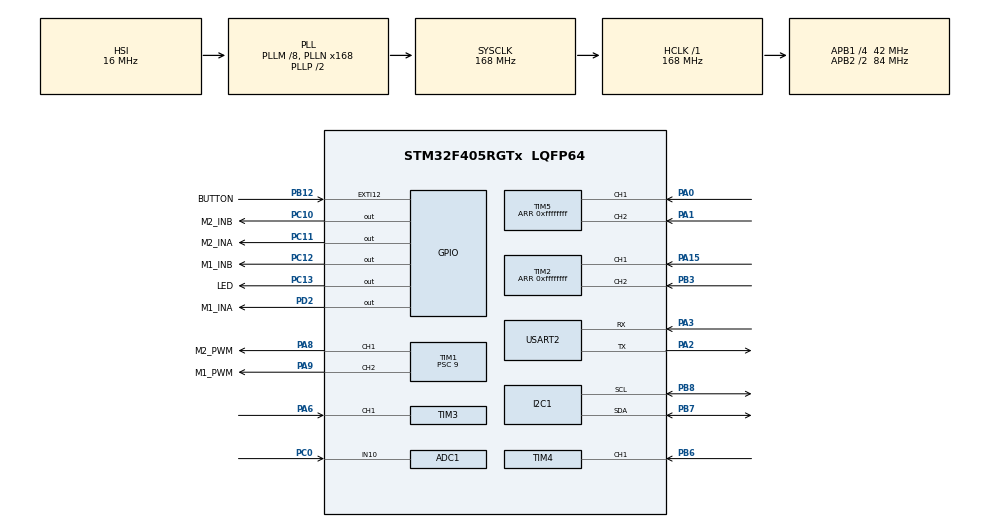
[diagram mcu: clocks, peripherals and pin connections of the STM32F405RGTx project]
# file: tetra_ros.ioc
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ADC1.Channel-4\#ChannelRegularConversion=ADC_CHANNEL_10
ADC1.Channel-5\#ChannelRegularConversion=ADC_CHANNEL_10
ADC1.ContinuousConvMode=ENABLE
ADC1.DMAContinuousRequests=ENABLE
ADC1.EOCSelection=ADC_EOC_SEQ_CONV
ADC1.ExternalTrigConv=ADC_SOFTWARE_START
ADC1.NbrOfConversion=2
ADC1.NbrOfConversionFlag=1
ADC1.Rank-4\#ChannelRegularConversion=1
ADC1.Rank-5\#ChannelRegularConversion=2
ADC1.SamplingTime-4\#ChannelRegularConversion=ADC_SAMPLETIME_480CYCLES
ADC1.SamplingTime-5\#ChannelRegularConversion=ADC_SAMPLETIME_480CYCLES
ADC1.ScanConvMode=ENABLE
ADC1.master=1
Dma.ADC1.2.Direction=DMA_PERIPH_TO_MEMORY
Dma.ADC1.2.FIFOMode=DMA_FIFOMODE_DISABLE
Dma.ADC1.2.Instance=DMA2_Stream0
Dma.ADC1.2.MemDataAlignment=DMA_MDATAALIGN_HALFWORD
Dma.ADC1.2.MemInc=DMA_MINC_ENABLE
Dma.ADC1.2.Mode=DMA_CIRCULAR
Dma.ADC1.2.PeriphDataAlignment=DMA_PDATAALIGN_HALFWORD
Dma.ADC1.2.PeriphInc=DMA_PINC_DISABLE
Dma.ADC1.2.Priority=DMA_PRIORITY_LOW
Dma.Request0=USART2_RX
Dma.Request1=USART2_TX
Dma.Request2=ADC1
Dma.USART2_RX.0.Direction=DMA_PERIPH_TO_MEMORY
Dma.USART2_RX.0.FIFOMode=DMA_FIFOMODE_DISABLE
Dma.USART2_RX.0.Instance=DMA1_Stream5
Dma.USART2_RX.0.MemDataAlignment=DMA_MDATAALIGN_BYTE
Dma.USART2_RX.0.MemInc=DMA_MINC_ENABLE
Dma.USART2_RX.0.Mode=DMA_CIRCULAR
Dma.USART2_RX.0.PeriphDataAlignment=DMA_PDATAALIGN_BYTE
Dma.USART2_RX.0.PeriphInc=DMA_PINC_DISABLE
Dma.USART2_RX.0.Priority=DMA_PRIORITY_LOW
Dma.USART2_TX.1.Direction=DMA_MEMORY_TO_PERIPH
Dma.USART2_TX.1.FIFOMode=DMA_FIFOMODE_DISABLE
Dma.USART2_TX.1.Instance=DMA1_Stream6
Dma.USART2_TX.1.MemDataAlignment=DMA_MDATAALIGN_BYTE
Dma.USART2_TX.1.MemInc=DMA_MINC_ENABLE
Dma.USART2_TX.1.Mode=DMA_NORMAL
Dma.USART2_TX.1.PeriphDataAlignment=DMA_PDATAALIGN_BYTE
Dma.USART2_TX.1.PeriphInc=DMA_PINC_DISABLE
Dma.USART2_TX.1.Priority=DMA_PRIORITY_LOW
I2C1.I2C_Mode=I2C_Fast
Mcu.Family=STM32F4
Mcu.Name=STM32F405RGTx
Mcu.Package=LQFP64
NVIC.DMA1_Stream5_IRQn=true\:0\:0\:false\:false\:true\:false\:true
NVIC.DMA1_Stream6_IRQn=true\:0\:0\:false\:false\:true\:false\:true
NVIC.DMA2_Stream0_IRQn=true\:0\:0\:false\:false\:true\:true\:true
NVIC.EXTI15_10_IRQn=true\:0\:0\:false\:false\:true\:true\:true
NVIC.PriorityGroup=NVIC_PRIORITYGROUP_4
NVIC.TIM3_IRQn=true\:0\:0\:false\:false\:true\:true\:true
NVIC.USART2_IRQn=true\:0\:0\:false\:false\:true\:true\:true
PA0-WKUP.Signal=S_TIM5_CH1
PA1.Signal=S_TIM5_CH2
PA13.Mode=Serial_Wire
PA13.Signal=SYS_JTMS-SWDIO
PA14.Mode=Serial_Wire
PA14.Signal=SYS_JTCK-SWCLK
PA15.Signal=S_TIM2_CH1_ETR
PA2.Mode=Asynchronous
PA2.Signal=USART2_TX
PA3.Mode=Asynchronous
PA3.Signal=USART2_RX
PA6.Signal=S_TIM3_CH1
PA8.GPIO_Label=M2_PWM
PA8.Signal=S_TIM1_CH1
PA9.GPIO_Label=M1_PWM
PA9.Signal=S_TIM1_CH2
PB12.GPIO_Label=BUTTON
PB12.GPIO_ModeDefaultEXTI=GPIO_MODE_IT_FALLING
PB12.Signal=GPXTI12
PB3.Signal=S_TIM2_CH2
PB6.Signal=S_TIM4_CH1
PB7.Mode=I2C
PB7.Signal=I2C1_SDA
PB8.Mode=I2C
PB8.Signal=I2C1_SCL
PC0.Signal=ADCx_IN10
PC10.GPIO_Label=M2_INB
PC10.Signal=GPIO_Output
PC11.GPIO_Label=M2_INA
PC11.Signal=GPIO_Output
PC12.GPIO_Label=M1_INB
PC12.Signal=GPIO_Output
PC13-ANTI_TAMP.GPIO_Label=LED
PC13-ANTI_TAMP.Signal=GPIO_Output
PD2.GPIO_Label=M1_INA
PD2.Signal=GPIO_Output
ProjectManager.HeapSize=0x200
ProjectManager.StackSize=0x400
ProjectManager.TargetToolchain=STM32CubeIDE
RCC.48MHZClocksFreq_Value=84000000
RCC.AHBFreq_Value=168000000
RCC.APB1CLKDivider=RCC_HCLK_DIV4
RCC.APB1Freq_Value=42000000
RCC.APB1TimFreq_Value=84000000
RCC.APB2CLKDivider=RCC_HCLK_DIV2
RCC.APB2Freq_Value=84000000
RCC.APB2TimFreq_Value=168000000
RCC.CortexFreq_Value=168000000
RCC.HCLKFreq_Value=168000000
RCC.HSE_VALUE=25000000
RCC.HSI_VALUE=16000000
RCC.LSE_VALUE=32768
RCC.PLLM=8
RCC.PLLN=168
RCC.SYSCLKFreq_VALUE=168000000
RCC.SYSCLKSource=RCC_SYSCLKSOURCE_PLLCLK
RCC.VCOOutputFreq_Value=336000000
SH.ADCx_IN10.0=ADC1_IN10,IN10
SH.S_TIM1_CH1.0=TIM1_CH1,PWM Generation1 CH1
SH.S_TIM1_CH2.0=TIM1_CH2,PWM Generation2 CH2
SH.S_TIM2_CH1_ETR.0=TIM2_CH1,Encoder_Interface
SH.S_TIM2_CH2.0=TIM2_CH2,Encoder_Interface
SH.S_TIM3_CH1.0=TIM3_CH1,PWM_Input_1
SH.S_TIM4_CH1.0=TIM4_CH1,PWM_Input_1
SH.S_TIM5_CH1.0=TIM5_CH1,Encoder_Interface
SH.S_TIM5_CH2.0=TIM5_CH2,Encoder_Interface
TIM1.Channel-PWM\ Generation1\ CH1=TIM_CHANNEL_1
TIM1.Channel-PWM\ Generation2\ CH2=TIM_CHANNEL_2
TIM1.Period=999
TIM1.Prescaler=9
TIM14.Period=0xFFFF
TIM14.Prescaler=83
TIM2.EncoderMode=TIM_ENCODERMODE_TI12
TIM2.Period=0xffffffff
TIM3.Period=19999
TIM3.Prescaler=83
TIM4.Period=19999
TIM4.Prescaler=83
TIM5.EncoderMode=TIM_ENCODERMODE_TI12
TIM5.Period=0xffffffff
USART2.VirtualMode=VM_ASYNC
VP_IWDG_VS_IWDG.Mode=IWDG_Activate
VP_TIM14_VS_ClockSourceINT.Mode=Enable_Timer
VP_TIM1_VS_ClockSourceINT.Mode=Internal
VP_TIM3_VS_ClockSourceINT.Mode=Internal
VP_TIM4_VS_ClockSourceINT.Mode=Internal
board=SouthBridge

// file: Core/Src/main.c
/* USER CODE BEGIN Header */
/**
  ******************************************************************************
  * @file           : main.c
  * @brief          : Main program body
  ******************************************************************************
  * @attention
  *
  * <h2><center>&copy; Copyright (c) 2020 STMicroelectronics.
  * All rights reserved.</center></h2>
  *
  * This software component is licensed by ST under BSD 3-Clause license,
  * the "License"; You may not use this file except in compliance with the
  * License. You may obtain a copy of the License at:
  *                        opensource.org/licenses/BSD-3-Clause
  *
  ******************************************************************************
  */
/* USER CODE END Header */

#include "main.h"
#include "tetraROS.h"

ADC_HandleTypeDef hadc1;
DMA_HandleTypeDef hdma_adc1;

I2C_HandleTypeDef hi2c1;

TIM_HandleTypeDef htim1;
TIM_HandleTypeDef htim3;
TIM_HandleTypeDef htim4;

UART_HandleTypeDef huart2;
DMA_HandleTypeDef hdma_usart2_rx;
DMA_HandleTypeDef hdma_usart2_tx;

void SystemClock_Config(void);
static void MX_GPIO_Init(void);
static void MX_DMA_Init(void);
static void MX_TIM1_Init(void);
static void MX_TIM2_Init(void);
static void MX_TIM5_Init(void);
static void MX_ADC1_Init(void);
static void MX_TIM3_Init(void);
static void MX_TIM4_Init(void);
static void MX_USART2_UART_Init(void);
static void MX_I2C1_Init(void);
static void MX_TIM14_Init(void);
static void MX_IWDG_Init(void);

int main(void)
{

  /* MCU Configuration--------------------------------------------------------*/

  /* Reset of all peripherals, Initializes the Flash interface and the Systick. */
  HAL_Init();

  /* Configure the system clock */
  SystemClock_Config();

  /* Initialize all configured peripherals */
  MX_GPIO_Init();
  MX_DMA_Init();
  MX_TIM1_Init();
  MX_TIM2_Init();
  MX_TIM5_Init();
  MX_ADC1_Init();
  MX_TIM3_Init();
  MX_TIM4_Init();
  MX_USART2_UART_Init();
  MX_I2C1_Init();
  MX_TIM14_Init();
  MX_IWDG_Init();
  /* USER CODE BEGIN 2 */
  initTetraROS();
  /* USER CODE END 2 */

  /* Infinite loop */
  while (1)
  {

    /* USER CODE BEGIN 3 */
	  loopTetraROS();
  }
  /* USER CODE END 3 */
}

void SystemClock_Config(void)
{
  RCC_OscInitTypeDef RCC_OscInitStruct = {0};
  RCC_ClkInitTypeDef RCC_ClkInitStruct = {0};

  /** Configure the main internal regulator output voltage
  */
  __HAL_RCC_PWR_CLK_ENABLE();
  __HAL_PWR_VOLTAGESCALING_CONFIG(PWR_REGULATOR_VOLTAGE_SCALE1);
  /** Initializes the CPU, AHB and APB busses clocks
  */
  RCC_OscInitStruct.OscillatorType = RCC_OSCILLATORTYPE_HSI|RCC_OSCILLATORTYPE_LSI;
  RCC_OscInitStruct.HSIState = RCC_HSI_ON;
  RCC_OscInitStruct.HSICalibrationValue = RCC_HSICALIBRATION_DEFAULT;
  RCC_OscInitStruct.LSIState = RCC_LSI_ON;
  RCC_OscInitStruct.PLL.PLLState = RCC_PLL_ON;
  RCC_OscInitStruct.PLL.PLLSource = RCC_PLLSOURCE_HSI;
  RCC_OscInitStruct.PLL.PLLM = 8;
  RCC_OscInitStruct.PLL.PLLN = 168;
  RCC_OscInitStruct.PLL.PLLP = RCC_PLLP_DIV2;
  RCC_OscInitStruct.PLL.PLLQ = 4;
  if (HAL_RCC_OscConfig(&RCC_OscInitStruct) != HAL_OK)
  {
    Error_Handler();
  }
  /** Initializes the CPU, AHB and APB busses clocks
  */
  RCC_ClkInitStruct.ClockType = RCC_CLOCKTYPE_HCLK|RCC_CLOCKTYPE_SYSCLK
                              |RCC_CLOCKTYPE_PCLK1|RCC_CLOCKTYPE_PCLK2;
  RCC_ClkInitStruct.SYSCLKSource = RCC_SYSCLKSOURCE_PLLCLK;
  RCC_ClkInitStruct.AHBCLKDivider = RCC_SYSCLK_DIV1;
  RCC_ClkInitStruct.APB1CLKDivider = RCC_HCLK_DIV4;
  RCC_ClkInitStruct.APB2CLKDivider = RCC_HCLK_DIV2;

  if (HAL_RCC_ClockConfig(&RCC_ClkInitStruct, FLASH_LATENCY_5) != HAL_OK)
  {
    Error_Handler();
  }
}

static void MX_ADC1_Init(void)
{

  ADC_ChannelConfTypeDef sConfig = {0};

  /** Configure the global features of the ADC (Clock, Resolution, Data Alignment and number of conversion)
  */
  hadc1.Instance = ADC1;
  hadc1.Init.ClockPrescaler = ADC_CLOCK_SYNC_PCLK_DIV4;
  hadc1.Init.Resolution = ADC_RESOLUTION_12B;
  hadc1.Init.ScanConvMode = ENABLE;
  hadc1.Init.ContinuousConvMode = ENABLE;
  hadc1.Init.DiscontinuousConvMode = DISABLE;
  hadc1.Init.ExternalTrigConvEdge = ADC_EXTERNALTRIGCONVEDGE_NONE;
  hadc1.Init.ExternalTrigConv = ADC_SOFTWARE_START;
  hadc1.Init.DataAlign = ADC_DATAALIGN_RIGHT;
  hadc1.Init.NbrOfConversion = 2;
  hadc1.Init.DMAContinuousRequests = ENABLE;
  hadc1.Init.EOCSelection = ADC_EOC_SEQ_CONV;
  if (HAL_ADC_Init(&hadc1) != HAL_OK)
  {
    Error_Handler();
  }
  /** Configure for the selected ADC regular channel its corresponding rank in the sequencer and its sample time.
  */
  sConfig.Channel = ADC_CHANNEL_10;
  sConfig.Rank = 1;
  sConfig.SamplingTime = ADC_SAMPLETIME_480CYCLES;
  if (HAL_ADC_ConfigChannel(&hadc1, &sConfig) != HAL_OK)
  {
    Error_Handler();
  }
  /** Configure for the selected ADC regular channel its corresponding rank in the sequencer and its sample time.
  */
  sConfig.Rank = 2;
  if (HAL_ADC_ConfigChannel(&hadc1, &sConfig) != HAL_OK)
  {
    Error_Handler();
  }

}

static void MX_I2C1_Init(void)
{

  hi2c1.Instance = I2C1;
  hi2c1.Init.ClockSpeed = 400000;
  hi2c1.Init.DutyCycle = I2C_DUTYCYCLE_2;
  hi2c1.Init.OwnAddress1 = 0;
  hi2c1.Init.AddressingMode = I2C_ADDRESSINGMODE_7BIT;
  hi2c1.Init.DualAddressMode = I2C_DUALADDRESS_DISABLE;
  hi2c1.Init.OwnAddress2 = 0;
  hi2c1.Init.GeneralCallMode = I2C_GENERALCALL_DISABLE;
  hi2c1.Init.NoStretchMode = I2C_NOSTRETCH_DISABLE;
  if (HAL_I2C_Init(&hi2c1) != HAL_OK)
  {
    Error_Handler();
  }

}

static void MX_IWDG_Init(void)
{

  hiwdg.Instance = IWDG;
  hiwdg.Init.Prescaler = IWDG_PRESCALER_16;
  hiwdg.Init.Reload = 4095;
  if (HAL_IWDG_Init(&hiwdg) != HAL_OK)
  {
    Error_Handler();
  }

}

static void MX_TIM1_Init(void)
{

  TIM_ClockConfigTypeDef sClockSourceConfig = {0};
  TIM_MasterConfigTypeDef sMasterConfig = {0};
  TIM_OC_InitTypeDef sConfigOC = {0};
  TIM_BreakDeadTimeConfigTypeDef sBreakDeadTimeConfig = {0};

  htim1.Instance = TIM1;
  htim1.Init.Prescaler = 9;
  htim1.Init.CounterMode = TIM_COUNTERMODE_UP;
  htim1.Init.Period = 999;
  htim1.Init.ClockDivision = TIM_CLOCKDIVISION_DIV1;
  htim1.Init.RepetitionCounter = 0;
  htim1.Init.AutoReloadPreload = TIM_AUTORELOAD_PRELOAD_DISABLE;
  if (HAL_TIM_Base_Init(&htim1) != HAL_OK)
  {
    Error_Handler();
  }
  sClockSourceConfig.ClockSource = TIM_CLOCKSOURCE_INTERNAL;
  if (HAL_TIM_ConfigClockSource(&htim1, &sClockSourceConfig) != HAL_OK)
  {
    Error_Handler();
  }
  if (HAL_TIM_PWM_Init(&htim1) != HAL_OK)
  {
    Error_Handler();
  }
  sMasterConfig.MasterOutputTrigger = TIM_TRGO_RESET;
  sMasterConfig.MasterSlaveMode = TIM_MASTERSLAVEMODE_DISABLE;
  if (HAL_TIMEx_MasterConfigSynchronization(&htim1, &sMasterConfig) != HAL_OK)
  {
    Error_Handler();
  }
  sConfigOC.OCMode = TIM_OCMODE_PWM1;
  sConfigOC.Pulse = 0;
  sConfigOC.OCPolarity = TIM_OCPOLARITY_HIGH;
  sConfigOC.OCNPolarity = TIM_OCNPOLARITY_HIGH;
  sConfigOC.OCFastMode = TIM_OCFAST_DISABLE;
  sConfigOC.OCIdleState = TIM_OCIDLESTATE_RESET;
  sConfigOC.OCNIdleState = TIM_OCNIDLESTATE_RESET;
  if (HAL_TIM_PWM_ConfigChannel(&htim1, &sConfigOC, TIM_CHANNEL_1) != HAL_OK)
  {
    Error_Handler();
  }
  if (HAL_TIM_PWM_ConfigChannel(&htim1, &sConfigOC, TIM_CHANNEL_2) != HAL_OK)
  {
    Error_Handler();
  }
  sBreakDeadTimeConfig.OffStateRunMode = TIM_OSSR_DISABLE;
  sBreakDeadTimeConfig.OffStateIDLEMode = TIM_OSSI_DISABLE;
  sBreakDeadTimeConfig.LockLevel = TIM_LOCKLEVEL_OFF;
  sBreakDeadTimeConfig.DeadTime = 0;
  sBreakDeadTimeConfig.BreakState = TIM_BREAK_DISABLE;
  sBreakDeadTimeConfig.BreakPolarity = TIM_BREAKPOLARITY_HIGH;
  sBreakDeadTimeConfig.AutomaticOutput = TIM_AUTOMATICOUTPUT_DISABLE;
  if (HAL_TIMEx_ConfigBreakDeadTime(&htim1, &sBreakDeadTimeConfig) != HAL_OK)
  {
    Error_Handler();
  }
  HAL_TIM_MspPostInit(&htim1);

}

static void MX_TIM2_Init(void)
{

  TIM_Encoder_InitTypeDef sConfig = {0};
  TIM_MasterConfigTypeDef sMasterConfig = {0};

  htim2.Instance = TIM2;
  htim2.Init.Prescaler = 0;
  htim2.Init.CounterMode = TIM_COUNTERMODE_UP;
  htim2.Init.Period = 0xffffffff;
  htim2.Init.ClockDivision = TIM_CLOCKDIVISION_DIV1;
  htim2.Init.AutoReloadPreload = TIM_AUTORELOAD_PRELOAD_DISABLE;
  sConfig.EncoderMode = TIM_ENCODERMODE_TI12;
  sConfig.IC1Polarity = TIM_ICPOLARITY_RISING;
  sConfig.IC1Selection = TIM_ICSELECTION_DIRECTTI;
  sConfig.IC1Prescaler = TIM_ICPSC_DIV1;
  sConfig.IC1Filter = 0;
  sConfig.IC2Polarity = TIM_ICPOLARITY_RISING;
  sConfig.IC2Selection = TIM_ICSELECTION_DIRECTTI;
  sConfig.IC2Prescaler = TIM_ICPSC_DIV1;
  sConfig.IC2Filter = 0;
  if (HAL_TIM_Encoder_Init(&htim2, &sConfig) != HAL_OK)
  {
    Error_Handler();
  }
  sMasterConfig.MasterOutputTrigger = TIM_TRGO_RESET;
  sMasterConfig.MasterSlaveMode = TIM_MASTERSLAVEMODE_DISABLE;
  if (HAL_TIMEx_MasterConfigSynchronization(&htim2, &sMasterConfig) != HAL_OK)
  {
    Error_Handler();
  }

}

static void MX_TIM3_Init(void)
{

  TIM_ClockConfigTypeDef sClockSourceConfig = {0};
  TIM_SlaveConfigTypeDef sSlaveConfig = {0};
  TIM_IC_InitTypeDef sConfigIC = {0};
  TIM_MasterConfigTypeDef sMasterConfig = {0};

  htim3.Instance = TIM3;
  htim3.Init.Prescaler = 83;
  htim3.Init.CounterMode = TIM_COUNTERMODE_UP;
  htim3.Init.Period = 19999;
  htim3.Init.ClockDivision = TIM_CLOCKDIVISION_DIV1;
  htim3.Init.AutoReloadPreload = TIM_AUTORELOAD_PRELOAD_DISABLE;
  if (HAL_TIM_Base_Init(&htim3) != HAL_OK)
  {
    Error_Handler();
  }
  sClockSourceConfig.ClockSource = TIM_CLOCKSOURCE_INTERNAL;
  if (HAL_TIM_ConfigClockSource(&htim3, &sClockSourceConfig) != HAL_OK)
  {
    Error_Handler();
  }
  if (HAL_TIM_IC_Init(&htim3) != HAL_OK)
  {
    Error_Handler();
  }
  sSlaveConfig.SlaveMode = TIM_SLAVEMODE_RESET;
  sSlaveConfig.InputTrigger = TIM_TS_TI1FP1;
  sSlaveConfig.TriggerPolarity = TIM_INPUTCHANNELPOLARITY_RISING;
  sSlaveConfig.TriggerPrescaler = TIM_ICPSC_DIV1;
  sSlaveConfig.TriggerFilter = 0;
  if (HAL_TIM_SlaveConfigSynchro(&htim3, &sSlaveConfig) != HAL_OK)
  {
    Error_Handler();
  }
  sConfigIC.ICPolarity = TIM_INPUTCHANNELPOLARITY_RISING;
  sConfigIC.ICSelection = TIM_ICSELECTION_DIRECTTI;
  sConfigIC.ICPrescaler = TIM_ICPSC_DIV1;
  sConfigIC.ICFilter = 0;
  if (HAL_TIM_IC_ConfigChannel(&htim3, &sConfigIC, TIM_CHANNEL_1) != HAL_OK)
  {
    Error_Handler();
  }
  sConfigIC.ICPolarity = TIM_INPUTCHANNELPOLARITY_FALLING;
  sConfigIC.ICSelection = TIM_ICSELECTION_INDIRECTTI;
  if (HAL_TIM_IC_ConfigChannel(&htim3, &sConfigIC, TIM_CHANNEL_2) != HAL_OK)
  {
    Error_Handler();
  }
  sMasterConfig.MasterOutputTrigger = TIM_TRGO_RESET;
  sMasterConfig.MasterSlaveMode = TIM_MASTERSLAVEMODE_DISABLE;
  if (HAL_TIMEx_MasterConfigSynchronization(&htim3, &sMasterConfig) != HAL_OK)
  {
    Error_Handler();
  }

}

static void MX_TIM4_Init(void)
{

  TIM_ClockConfigTypeDef sClockSourceConfig = {0};
  TIM_SlaveConfigTypeDef sSlaveConfig = {0};
  TIM_IC_InitTypeDef sConfigIC = {0};
  TIM_MasterConfigTypeDef sMasterConfig = {0};

  htim4.Instance = TIM4;
  htim4.Init.Prescaler = 83;
  htim4.Init.CounterMode = TIM_COUNTERMODE_UP;
  htim4.Init.Period = 19999;
  htim4.Init.ClockDivision = TIM_CLOCKDIVISION_DIV1;
  htim4.Init.AutoReloadPreload = TIM_AUTORELOAD_PRELOAD_DISABLE;
  if (HAL_TIM_Base_Init(&htim4) != HAL_OK)
  {
    Error_Handler();
  }
  sClockSourceConfig.ClockSource = TIM_CLOCKSOURCE_INTERNAL;
  if (HAL_TIM_ConfigClockSource(&htim4, &sClockSourceConfig) != HAL_OK)
  {
    Error_Handler();
  }
  if (HAL_TIM_IC_Init(&htim4) != HAL_OK)
  {
    Error_Handler();
  }
  sSlaveConfig.SlaveMode = TIM_SLAVEMODE_RESET;
  sSlaveConfig.InputTrigger = TIM_TS_TI1FP1;
  sSlaveConfig.TriggerPolarity = TIM_INPUTCHANNELPOLARITY_RISING;
  sSlaveConfig.TriggerPrescaler = TIM_ICPSC_DIV1;
  sSlaveConfig.TriggerFilter = 0;
  if (HAL_TIM_SlaveConfigSynchro(&htim4, &sSlaveConfig) != HAL_OK)
  {
    Error_Handler();
  }
  sConfigIC.ICPolarity = TIM_INPUTCHANNELPOLARITY_RISING;
  sConfigIC.ICSelection = TIM_ICSELECTION_DIRECTTI;
  sConfigIC.ICPrescaler = TIM_ICPSC_DIV1;
  sConfigIC.ICFilter = 0;
  if (HAL_TIM_IC_ConfigChannel(&htim4, &sConfigIC, TIM_CHANNEL_1) != HAL_OK)
  {
    Error_Handler();
  }
  sConfigIC.ICPolarity = TIM_INPUTCHANNELPOLARITY_FALLING;
  sConfigIC.ICSelection = TIM_ICSELECTION_INDIRECTTI;
  if (HAL_TIM_IC_ConfigChannel(&htim4, &sConfigIC, TIM_CHANNEL_2) != HAL_OK)
  {
    Error_Handler();
  }
  sMasterConfig.MasterOutputTrigger = TIM_TRGO_RESET;
  sMasterConfig.MasterSlaveMode = TIM_MASTERSLAVEMODE_DISABLE;
  if (HAL_TIMEx_MasterConfigSynchronization(&htim4, &sMasterConfig) != HAL_OK)
  {
    Error_Handler();
  }

}

static void MX_TIM5_Init(void)
{

  TIM_Encoder_InitTypeDef sConfig = {0};
  TIM_MasterConfigTypeDef sMasterConfig = {0};

  htim5.Instance = TIM5;
  htim5.Init.Prescaler = 0;
  htim5.Init.CounterMode = TIM_COUNTERMODE_UP;
  htim5.Init.Period = 0xffffffff;
  htim5.Init.ClockDivision = TIM_CLOCKDIVISION_DIV1;
  htim5.Init.AutoReloadPreload = TIM_AUTORELOAD_PRELOAD_DISABLE;
  sConfig.EncoderMode = TIM_ENCODERMODE_TI12;
  sConfig.IC1Polarity = TIM_ICPOLARITY_RISING;
  sConfig.IC1Selection = TIM_ICSELECTION_DIRECTTI;
  sConfig.IC1Prescaler = TIM_ICPSC_DIV1;
  sConfig.IC1Filter = 0;
  sConfig.IC2Polarity = TIM_ICPOLARITY_RISING;
  sConfig.IC2Selection = TIM_ICSELECTION_DIRECTTI;
  sConfig.IC2Prescaler = TIM_ICPSC_DIV1;
  sConfig.IC2Filter = 0;
  if (HAL_TIM_Encoder_Init(&htim5, &sConfig) != HAL_OK)
  {
    Error_Handler();
  }
  sMasterConfig.MasterOutputTrigger = TIM_TRGO_RESET;
  sMasterConfig.MasterSlaveMode = TIM_MASTERSLAVEMODE_DISABLE;
  if (HAL_TIMEx_MasterConfigSynchronization(&htim5, &sMasterConfig) != HAL_OK)
  {
    Error_Handler();
  }

}

static void MX_TIM14_Init(void)
{

  htim14.Instance = TIM14;
  htim14.Init.Prescaler = 83;
  htim14.Init.CounterMode = TIM_COUNTERMODE_UP;
  htim14.Init.Period = 0xFFFF;
  htim14.Init.ClockDivision = TIM_CLOCKDIVISION_DIV1;
  htim14.Init.AutoReloadPreload = TIM_AUTORELOAD_PRELOAD_DISABLE;
  if (HAL_TIM_Base_Init(&htim14) != HAL_OK)
  {
    Error_Handler();
  }

}

static void MX_USART2_UART_Init(void)
{

  huart2.Instance = USART2;
  huart2.Init.BaudRate = 115200;
  huart2.Init.WordLength = UART_WORDLENGTH_8B;
  huart2.Init.StopBits = UART_STOPBITS_1;
  huart2.Init.Parity = UART_PARITY_NONE;
  huart2.Init.Mode = UART_MODE_TX_RX;
  huart2.Init.HwFlowCtl = UART_HWCONTROL_NONE;
  huart2.Init.OverSampling = UART_OVERSAMPLING_16;
  if (HAL_UART_Init(&huart2) != HAL_OK)
  {
    Error_Handler();
  }

}

static void MX_DMA_Init(void)
{

  /* DMA controller clock enable */
  __HAL_RCC_DMA1_CLK_ENABLE();
  __HAL_RCC_DMA2_CLK_ENABLE();

  /* DMA interrupt init */
  /* DMA1_Stream5_IRQn interrupt configuration */
  HAL_NVIC_SetPriority(DMA1_Stream5_IRQn, 0, 0);
  HAL_NVIC_EnableIRQ(DMA1_Stream5_IRQn);
  /* DMA1_Stream6_IRQn interrupt configuration */
  HAL_NVIC_SetPriority(DMA1_Stream6_IRQn, 0, 0);
  HAL_NVIC_EnableIRQ(DMA1_Stream6_IRQn);
  /* DMA2_Stream0_IRQn interrupt configuration */
  HAL_NVIC_SetPriority(DMA2_Stream0_IRQn, 0, 0);
  HAL_NVIC_EnableIRQ(DMA2_Stream0_IRQn);

}

static void MX_GPIO_Init(void)
{
  GPIO_InitTypeDef GPIO_InitStruct = {0};

  /* GPIO Ports Clock Enable */
  __HAL_RCC_GPIOC_CLK_ENABLE();
  __HAL_RCC_GPIOA_CLK_ENABLE();
  __HAL_RCC_GPIOB_CLK_ENABLE();
  __HAL_RCC_GPIOD_CLK_ENABLE();

  /*Configure GPIO pin Output Level */
  HAL_GPIO_WritePin(GPIOC, LED_Pin|M2_INB_Pin|M2_INA_Pin|M1_INB_Pin, GPIO_PIN_RESET);

  /*Configure GPIO pin Output Level */
  HAL_GPIO_WritePin(M1_INA_GPIO_Port, M1_INA_Pin, GPIO_PIN_RESET);

  /*Configure GPIO pins : LED_Pin M2_INB_Pin M2_INA_Pin M1_INB_Pin */
  GPIO_InitStruct.Pin = LED_Pin|M2_INB_Pin|M2_INA_Pin|M1_INB_Pin;
  GPIO_InitStruct.Mode = GPIO_MODE_OUTPUT_PP;
  GPIO_InitStruct.Pull = GPIO_NOPULL;
  GPIO_InitStruct.Speed = GPIO_SPEED_FREQ_LOW;
  HAL_GPIO_Init(GPIOC, &GPIO_InitStruct);

  /*Configure GPIO pin : BUTTON_Pin */
  GPIO_InitStruct.Pin = BUTTON_Pin;
  GPIO_InitStruct.Mode = GPIO_MODE_IT_FALLING;
  GPIO_InitStruct.Pull = GPIO_NOPULL;
  HAL_GPIO_Init(BUTTON_GPIO_Port, &GPIO_InitStruct);

  /*Configure GPIO pin : M1_INA_Pin */
  GPIO_InitStruct.Pin = M1_INA_Pin;
  GPIO_InitStruct.Mode = GPIO_MODE_OUTPUT_PP;
  GPIO_InitStruct.Pull = GPIO_NOPULL;
  GPIO_InitStruct.Speed = GPIO_SPEED_FREQ_LOW;
  HAL_GPIO_Init(M1_INA_GPIO_Port, &GPIO_InitStruct);

  /* EXTI interrupt init*/
  HAL_NVIC_SetPriority(EXTI15_10_IRQn, 0, 0);
  HAL_NVIC_EnableIRQ(EXTI15_10_IRQn);

}

void Error_Handler(void)
{
}

/************************ (C) COPYRIGHT STMicroelectronics *****END OF FILE****/
